VERSION ""

NS_ :

BS_:

BU_: XXX

BO_ 496 NEW_MSG_1: 8 XXX
 SG_ NEW_SIGNAL_1 : 0|8@1+ (1,0) [0|255] "" XXX

BO_ 809 NEW_MSG_2: 8 XXX

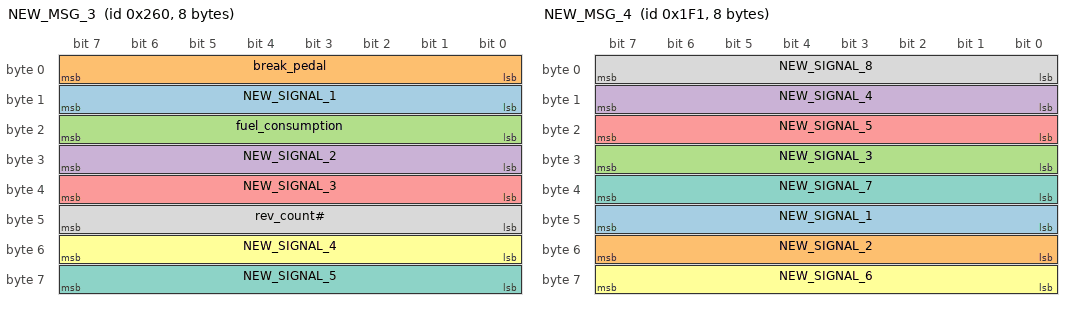
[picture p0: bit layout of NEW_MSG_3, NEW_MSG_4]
BO_ 608 NEW_MSG_3: 8 XXX
 SG_ NEW_SIGNAL_1 : 8|8@1+ (1,0) [0|255] "" XXX
 SG_ break_pedal : 0|8@1+ (1,0) [0|255] "" XXX
 SG_ fuel_consumption : 23|8@0+ (1,0) [0|255] "" XXX
 SG_ NEW_SIGNAL_2 : 31|8@0+ (1,0) [0|255] "" XXX
 SG_ NEW_SIGNAL_3 : 39|8@0+ (1,0) [0|255] "" XXX
 SG_ NEW_SIGNAL_4 : 55|8@0+ (1,0) [0|255] "" XXX
 SG_ NEW_SIGNAL_5 : 63|8@0+ (1,0) [0|255] "" XXX
 SG_ rev_count# : 47|8@0+ (1,0) [0|255] "" XXX

BO_ 497 NEW_MSG_4: 8 XXX
 SG_ NEW_SIGNAL_1 : 47|8@0+ (1,0) [0|255] "" XXX
 SG_ NEW_SIGNAL_2 : 55|8@0+ (1,0) [0|255] "" XXX
 SG_ NEW_SIGNAL_3 : 31|8@0+ (1,0) [0|255] "" XXX
 SG_ NEW_SIGNAL_4 : 15|8@0+ (1,0) [0|255] "" XXX
 SG_ NEW_SIGNAL_5 : 16|8@1+ (1,0) [0|255] "" XXX
 SG_ NEW_SIGNAL_6 : 63|8@0+ (1,0) [0|255] "" XXX
 SG_ NEW_SIGNAL_7 : 39|8@0+ (1,0) [0|255] "" XXX
 SG_ NEW_SIGNAL_8 : 7|8@0+ (1,0) [0|255] "" XXX

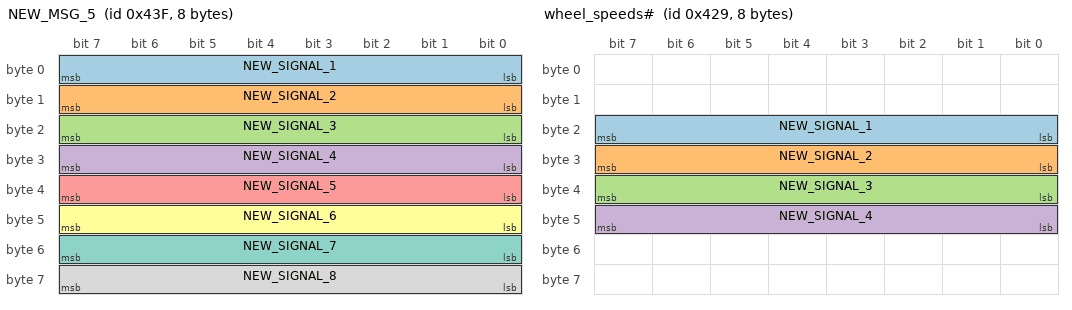
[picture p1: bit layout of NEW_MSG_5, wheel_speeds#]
BO_ 1087 NEW_MSG_5: 8 XXX
 SG_ NEW_SIGNAL_1 : 7|8@0+ (1,0) [0|255] "" XXX
 SG_ NEW_SIGNAL_2 : 15|8@0+ (1,0) [0|255] "" XXX
 SG_ NEW_SIGNAL_3 : 23|8@0+ (1,0) [0|255] "" XXX
 SG_ NEW_SIGNAL_4 : 31|8@0+ (1,0) [0|255] "" XXX
 SG_ NEW_SIGNAL_5 : 39|8@0+ (1,0) [0|255] "" XXX
 SG_ NEW_SIGNAL_6 : 47|8@0+ (1,0) [0|255] "" XXX
 SG_ NEW_SIGNAL_7 : 55|8@0+ (1,0) [0|255] "" XXX
 SG_ NEW_SIGNAL_8 : 63|8@0+ (1,0) [0|255] "" XXX

BO_ 1065 wheel_speeds#: 8 XXX
 SG_ NEW_SIGNAL_1 : 23|8@0+ (1,0) [0|255] "" XXX
 SG_ NEW_SIGNAL_2 : 31|8@0+ (1,0) [0|255] "" XXX
 SG_ NEW_SIGNAL_3 : 39|8@0+ (1,0) [0|255] "" XXX
 SG_ NEW_SIGNAL_4 : 47|8@0+ (1,0) [0|255] "" XXX

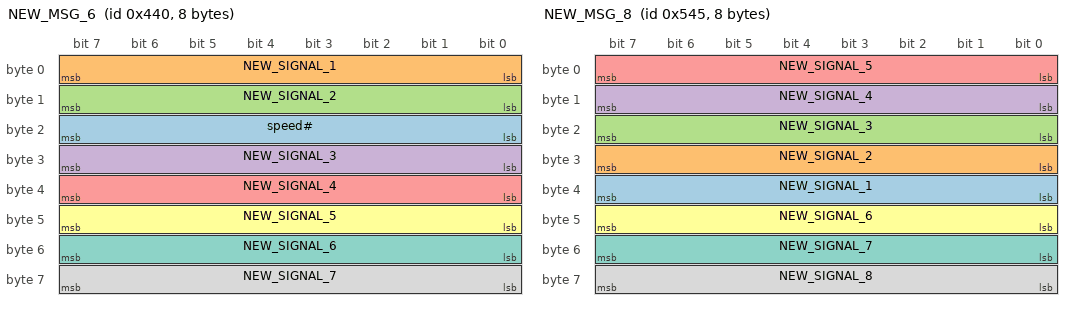
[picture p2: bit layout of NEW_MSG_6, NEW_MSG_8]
BO_ 1088 NEW_MSG_6: 8 XXX
 SG_ speed# : 23|8@0+ (1,0) [0|255] "" XXX
 SG_ NEW_SIGNAL_1 : 7|8@0+ (1,0) [0|255] "" XXX
 SG_ NEW_SIGNAL_2 : 15|8@0+ (1,0) [0|255] "" XXX
 SG_ NEW_SIGNAL_3 : 31|8@0+ (1,0) [0|255] "" XXX
 SG_ NEW_SIGNAL_4 : 39|8@0+ (1,0) [0|255] "" XXX
 SG_ NEW_SIGNAL_5 : 47|8@0+ (1,0) [0|255] "" XXX
 SG_ NEW_SIGNAL_6 : 55|8@0+ (1,0) [0|255] "" XXX
 SG_ NEW_SIGNAL_7 : 63|8@0+ (1,0) [0|255] "" XXX

BO_ 790 NEW_MSG_7: 8 XXX

BO_ 1349 NEW_MSG_8: 8 XXX
 SG_ NEW_SIGNAL_1 : 39|8@0+ (1,0) [0|255] "" XXX
 SG_ NEW_SIGNAL_2 : 24|8@1+ (1,0) [0|255] "" XXX
 SG_ NEW_SIGNAL_3 : 23|8@0+ (1,0) [0|255] "" XXX
 SG_ NEW_SIGNAL_4 : 15|8@0+ (1,0) [0|255] "" XXX
 SG_ NEW_SIGNAL_5 : 7|8@0+ (1,0) [0|255] "" XXX
 SG_ NEW_SIGNAL_6 : 47|8@0+ (1,0) [0|255] "" XXX
 SG_ NEW_SIGNAL_7 : 55|8@0+ (1,0) [0|255] "" XXX
 SG_ NEW_SIGNAL_8 : 63|8@0+ (1,0) [0|255] "" XXX

BO_ 1064 NEW_MSG_9: 8 XXX
 SG_ NEW_SIGNAL_1 : 23|8@0+ (1,0) [0|255] "" XXX
 SG_ NEW_SIGNAL_2 : 55|8@0+ (1,0) [0|255] "" XXX

BO_ 339 static1#: 8 XXX

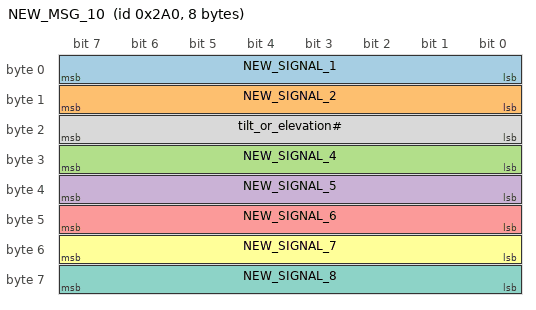
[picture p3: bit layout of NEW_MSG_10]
BO_ 672 NEW_MSG_10: 8 XXX
 SG_ NEW_SIGNAL_1 : 7|8@0+ (1,0) [0|255] "" XXX
 SG_ NEW_SIGNAL_2 : 15|8@0+ (1,0) [0|255] "" XXX
 SG_ NEW_SIGNAL_4 : 31|8@0+ (1,0) [0|255] "" XXX
 SG_ NEW_SIGNAL_5 : 39|8@0+ (1,0) [0|255] "" XXX
 SG_ NEW_SIGNAL_6 : 47|8@0+ (1,0) [0|255] "" XXX
 SG_ NEW_SIGNAL_7 : 55|8@0+ (1,0) [0|255] "" XXX
 SG_ NEW_SIGNAL_8 : 63|8@0+ (1,0) [0|255] "" XXX
 SG_ tilt_or_elevation# : 23|8@0+ (1,0) [0|255] "" XXX
